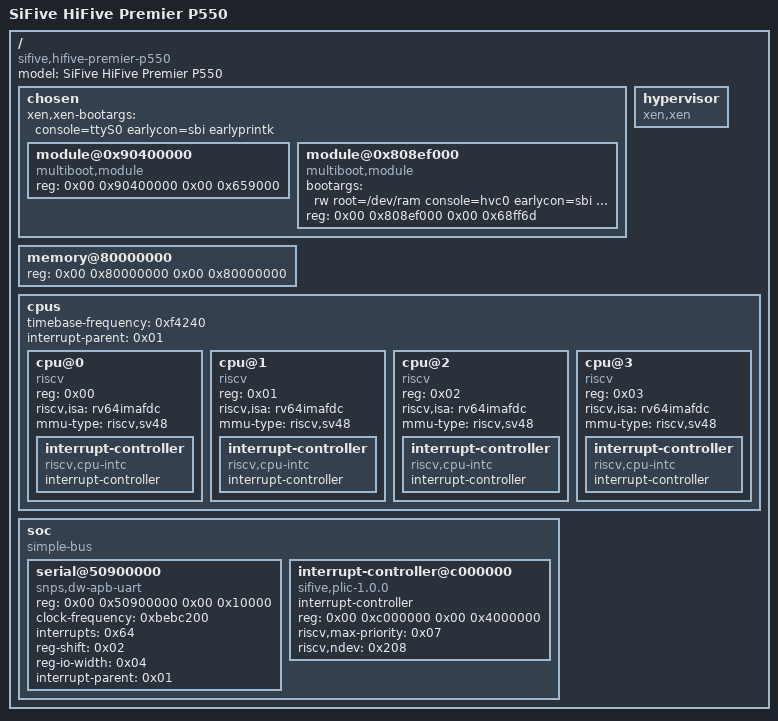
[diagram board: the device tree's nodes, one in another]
/dts-v1/;

/ {
	#address-cells = <0x02>;
	#size-cells = <0x02>;
	compatible = "sifive,hifive-premier-p550", "eswin,eic7700";
	model = "SiFive HiFive Premier P550";

	chosen {
		xen,xen-bootargs = "console=ttyS0 earlycon=sbi earlyprintk";

		module@0x90400000 {
			compatible = "multiboot,module", "multiboot,ramdisk";
			reg = <0x00 0x90400000 0x00 0x659000>;
		};
		
		module@0x808ef000 {
			bootargs = "rw root=/dev/ram console=hvc0 earlycon=sbi keep_bootcon bootmem_debug debug";
			compatible = "multiboot,module", "multiboot,kernel";
			reg = <0x00 0x808ef000 0x00 0x68ff6d>;
		};
	};

	hypervisor {
		compatible = "xen,xen";
		#address-cells = <0x02>;
		#size-cells = <0x02>;
	};

	memory@80000000 {
		device_type = "memory";
		reg = <0x00 0x80000000 0x00 0x80000000>;
	};

	cpus {
		#address-cells = <0x01>;
		#size-cells = <0x00>;
		timebase-frequency = <0xf4240>;
		interrupt-parent = <0x01>;

		cpu@0 {
			device_type = "cpu";
			compatible = "riscv";
			reg = <0x00>;
			riscv,isa = "rv64imafdc";
			mmu-type = "riscv,sv48";
			status = "okay";

			interrupt-controller {
				#interrupt-cells = <0x01>;
				interrupt-controller;
				compatible = "riscv,cpu-intc";
			};
		};

		cpu@1 {
			device_type = "cpu";
			compatible = "riscv";
			reg = <0x01>;
			riscv,isa = "rv64imafdc";
			mmu-type = "riscv,sv48";
			status = "okay";

			interrupt-controller {
				#interrupt-cells = <0x01>;
				interrupt-controller;
				compatible = "riscv,cpu-intc";
			};
		};

		cpu@2 {
			device_type = "cpu";
			compatible = "riscv";
			reg = <0x02>;
			riscv,isa = "rv64imafdc";
			mmu-type = "riscv,sv48";
			status = "okay";

			interrupt-controller {
				#interrupt-cells = <0x01>;
				interrupt-controller;
				compatible = "riscv,cpu-intc";
			};
		};

		cpu@3 {
			device_type = "cpu";
			compatible = "riscv";
			reg = <0x03>;
			riscv,isa = "rv64imafdc";
			mmu-type = "riscv,sv48";
			status = "okay";

			interrupt-controller {
				#interrupt-cells = <0x01>;
				interrupt-controller;
				compatible = "riscv,cpu-intc";
			};
		};
	};

	soc {
		#address-cells = <0x02>;
		#size-cells = <0x02>;
		compatible = "simple-bus";
		ranges;

		serial@50900000 {
			compatible = "snps,dw-apb-uart";
			reg = <0x00 0x50900000 0x00 0x10000>;
			clock-frequency = <0xbebc200>;
			interrupts = <0x64>;
			reg-shift = <0x02>;
			reg-io-width = <0x04>;
			status = "okay";
			interrupt-parent = <0x01>;
		};

		interrupt-controller@c000000 {
			compatible = "sifive,plic-1.0.0";
			interrupt-controller;
			#interrupt-cells = <0x01>;
			reg = <0x00 0xc000000 0x00 0x4000000>;
			riscv,max-priority = <0x07>;
			riscv,ndev = <0x208>;
			phandle = <0x01>;
		};
	};
};
